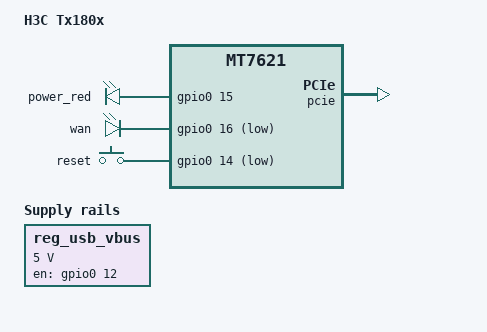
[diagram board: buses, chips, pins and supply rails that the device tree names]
/dts-v1/;

#include "mt7621.dtsi"
#include <dt-bindings/input/input.h>
#include "mt7621-spi-16m-layout.dtsi"
#include "mt7621-raeth-gmac2.dtsi"
#include "mt7621-pinctrl-default-gpio.dtsi"

  / {
	compatible = "mediatek,mt7621-soc";
	model = "H3C Tx180x";

	chosen {
		bootargs = "console=ttyS0,115200";
	};

	leds {
		compatible = "gpio-leds";

		sys_red {
			label = "power_red";
			gpios = <&gpio0 15 GPIO_ACTIVE_HIGH>;
		};

		wan {
			label = "wan";
			gpios = <&gpio0 16 GPIO_ACTIVE_LOW>;
		};
	};

	gpio-keys-polled {
		compatible = "gpio-keys-polled";
		#address-cells = <1>;
		#size-cells = <0>;
		poll-interval = <20>;

		reset {
			label = "reset";
			gpios = <&gpio0 14 GPIO_ACTIVE_LOW>;
			linux,code = <KEY_RESTART>;
		};
	};

	reg_usb_vbus: regulator {
		compatible = "regulator-fixed";
		regulator-name = "usb_vbus";
		regulator-min-microvolt = <5000000>;
		regulator-max-microvolt = <5000000>;
		gpio = <&gpio0 12 GPIO_ACTIVE_HIGH>;
		enable-active-high;
	};

	};
};

&pcie {
	status = "okay";
};
